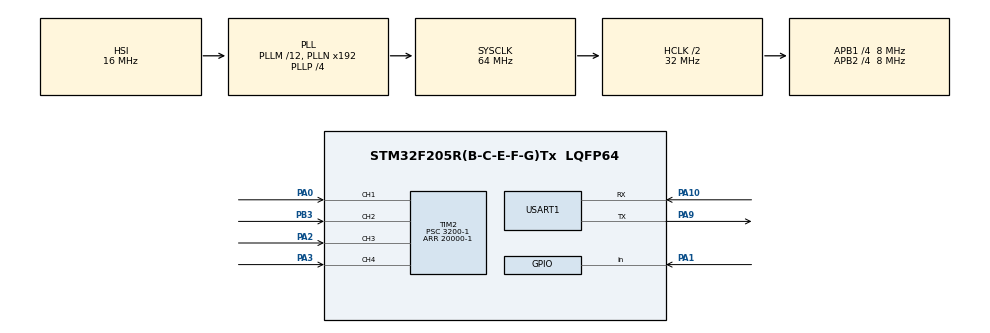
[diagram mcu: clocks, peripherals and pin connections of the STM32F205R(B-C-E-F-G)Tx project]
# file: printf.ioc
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Mcu.Family=STM32F2
Mcu.Name=STM32F205R(B-C-E-F-G)Tx
Mcu.Package=LQFP64
NVIC.PriorityGroup=NVIC_PRIORITYGROUP_4
NVIC.TIM2_IRQn=true\:0\:0\:false\:false\:true\:true\:true
PA0-WKUP.GPIO_ModeDefaultPP=GPIO_MODE_AF_OD
PA0-WKUP.GPIO_Speed=GPIO_SPEED_FREQ_VERY_HIGH
PA0-WKUP.Signal=S_TIM2_CH1_ETR
PA1.Signal=GPIO_Input
PA10.Mode=Asynchronous
PA10.Signal=USART1_RX
PA13.Mode=Serial_Wire
PA13.Signal=SYS_JTMS-SWDIO
PA14.Mode=Serial_Wire
PA14.Signal=SYS_JTCK-SWCLK
PA2.Signal=S_TIM2_CH3
PA3.Signal=S_TIM2_CH4
PA9.Mode=Asynchronous
PA9.Signal=USART1_TX
PB3.Signal=S_TIM2_CH2
PH0-OSC_IN.Mode=HSE-External-Oscillator
PH0-OSC_IN.Signal=RCC_OSC_IN
PH1-OSC_OUT.Mode=HSE-External-Oscillator
PH1-OSC_OUT.Signal=RCC_OSC_OUT
ProjectManager.HeapSize=0x200
ProjectManager.StackSize=0x400
ProjectManager.TargetToolchain=MDK-ARM V5
RCC.48MHZClocksFreq_Value=64000000
RCC.AHBCLKDivider=RCC_SYSCLK_DIV2
RCC.AHBFreq_Value=32000000
RCC.APB1CLKDivider=RCC_HCLK_DIV4
RCC.APB1Freq_Value=8000000
RCC.APB1TimFreq_Value=16000000
RCC.APB2CLKDivider=RCC_HCLK_DIV4
RCC.APB2Freq_Value=8000000
RCC.APB2TimFreq_Value=16000000
RCC.CortexFreq_Value=32000000
RCC.HCLKFreq_Value=32000000
RCC.HSE_VALUE=8000000
RCC.HSI_VALUE=16000000
RCC.LSE_VALUE=32768
RCC.PLLM=12
RCC.PLLP=RCC_PLLP_DIV4
RCC.SYSCLKFreq_VALUE=64000000
RCC.SYSCLKSource=RCC_SYSCLKSOURCE_PLLCLK
RCC.VCOOutputFreq_Value=256000000
SH.S_TIM2_CH1_ETR.0=TIM2_CH1,Input_Capture1_from_TI1
SH.S_TIM2_CH2.0=TIM2_CH2,Input_Capture2_from_TI2
SH.S_TIM2_CH3.0=TIM2_CH3,Input_Capture3_from_TI3
SH.S_TIM2_CH4.0=TIM2_CH4,Input_Capture4_from_TI4
TIM2.Channel-Input_Capture1_from_TI1=TIM_CHANNEL_1
TIM2.Channel-Input_Capture2_from_TI2=TIM_CHANNEL_2
TIM2.Channel-Input_Capture3_from_TI3=TIM_CHANNEL_3
TIM2.Channel-Input_Capture4_from_TI4=TIM_CHANNEL_4
TIM2.ICPolarity_CH1=TIM_INPUTCHANNELPOLARITY_BOTHEDGE
TIM2.ICPolarity_CH3=TIM_INPUTCHANNELPOLARITY_FALLING
TIM2.ICPolarity_CH4=TIM_INPUTCHANNELPOLARITY_BOTHEDGE
TIM2.Period=20000-1
TIM2.Prescaler=3200-1
USART1.VirtualMode=VM_ASYNC
board=custom

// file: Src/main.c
/* USER CODE BEGIN Header */
/**
  ******************************************************************************
  * @file           : main.c
  * @brief          : Main program body
  ******************************************************************************
  * @attention
  *
  * <h2><center>&copy; Copyright (c) 2019 STMicroelectronics.
  * All rights reserved.</center></h2>
  *
  * This software component is licensed by ST under BSD 3-Clause license,
  * the "License"; You may not use this file except in compliance with the
  * License. You may obtain a copy of the License at:
  *                        opensource.org/licenses/BSD-3-Clause
  *
  ******************************************************************************
  */
/* USER CODE END Header */

#include "main.h"

TIM_HandleTypeDef htim2;

UART_HandleTypeDef huart1;

/* USER CODE BEGIN PV */
uint16_t 	Channel1HighTime, Channel2HighTime, Channel3HighTime, Channel4HighTime;
uint16_t 	Channel1Period, Channel2Period, Channel3Period, Channel4Period;
uint8_t  	Channel1Edge = 0, Channel2Edge = 0, Channel3Edge = 0, Channel4Edge = 0;
uint16_t 	Channel1Percent, Channel2Percent, Channel3Percent, Channel4Percent;
uint16_t	Channel1PercentTemp[3] = {0, 0, 0};
uint8_t 	Channel1TempCount = 0;
uint16_t 	Channel1RisingTimeLast=0, Channel1RisingTimeNow, Channel1FallingTime;
uint16_t 	Channel2RisingTimeLast=0, Channel2RisingTimeNow, Channel2FallingTime;
uint16_t 	Channel3RisingTimeLast=0, Channel3RisingTimeNow, Channel3FallingTime;
uint16_t 	Channel4RisingTimeLast=0, Channel4RisingTimeNow, Channel4FallingTime;
/* USER CODE END PV */

void SystemClock_Config(void);
static void MX_GPIO_Init(void);
static void MX_USART1_UART_Init(void);
static void MX_TIM2_Init(void);

/* USER CODE BEGIN 0 */
int fputc(int ch,FILE *f)
{
uint8_t temp[1]={ch};
HAL_UART_Transmit(&huart1,temp,1,2);
return(ch);
}
/* USER CODE END 0 */

int main(void)
{

  /* MCU Configuration--------------------------------------------------------*/

  /* Reset of all peripherals, Initializes the Flash interface and the Systick. */
  HAL_Init();

  /* Configure the system clock */
  SystemClock_Config();

  /* Initialize all configured peripherals */
  MX_GPIO_Init();
  MX_USART1_UART_Init();
  MX_TIM2_Init();
	HAL_TIM_IC_Start_IT(&htim2, TIM_CHANNEL_1);
	HAL_TIM_IC_Start_IT(&htim2, TIM_CHANNEL_2);
	HAL_TIM_IC_Start_IT(&htim2, TIM_CHANNEL_3);
	HAL_TIM_IC_Start_IT(&htim2, TIM_CHANNEL_4);

  /* Infinite loop */
  while (1)
  {
//		printf("Channel1RisingTimeLast:%d\n",Channel1RisingTimeLast);
//		printf("Channel1RisingTimeNow:%d\n",Channel1RisingTimeNow);
//		printf("Channel1FallingTime:%d\n",Channel1FallingTime);
//		printf("\n\n");
//		printf("Channel2RisingTimeLast:%d\n",Channel2RisingTimeLast);
//		printf("Channel2RisingTimeNow:%d\n",Channel2RisingTimeNow);
//		printf("Channel2FallingTime:%d\n",Channel2FallingTime);
//		printf("\n\n");
//		printf("Channel3RisingTimeLast:%d\n",Channel3RisingTimeLast);
//		printf("Channel3RisingTimeNow:%d\n",Channel3RisingTimeNow);
//		printf("Channel3FallingTime:%d\n",Channel3FallingTime);
//		printf("\n\n");
//		printf("Channel4RisingTimeLast:%d\n",Channel4RisingTimeLast);
//		printf("Channel4RisingTimeNow:%d\n",Channel4RisingTimeNow);
//		printf("Channel4FallingTime:%d\n",Channel4FallingTime);
//		printf("\n\n");
//		HAL_Delay (3000);
  }
}

void SystemClock_Config(void)
{
  RCC_OscInitTypeDef RCC_OscInitStruct = {0};
  RCC_ClkInitTypeDef RCC_ClkInitStruct = {0};

  /** Initializes the CPU, AHB and APB busses clocks
  */
  RCC_OscInitStruct.OscillatorType = RCC_OSCILLATORTYPE_HSI;
  RCC_OscInitStruct.HSIState = RCC_HSI_ON;
  RCC_OscInitStruct.HSICalibrationValue = RCC_HSICALIBRATION_DEFAULT;
  RCC_OscInitStruct.PLL.PLLState = RCC_PLL_ON;
  RCC_OscInitStruct.PLL.PLLSource = RCC_PLLSOURCE_HSI;
  RCC_OscInitStruct.PLL.PLLM = 12;
  RCC_OscInitStruct.PLL.PLLN = 192;
  RCC_OscInitStruct.PLL.PLLP = RCC_PLLP_DIV4;
  RCC_OscInitStruct.PLL.PLLQ = 4;
  if (HAL_RCC_OscConfig(&RCC_OscInitStruct) != HAL_OK)
  {
    Error_Handler();
  }
  /** Initializes the CPU, AHB and APB busses clocks
  */
  RCC_ClkInitStruct.ClockType = RCC_CLOCKTYPE_HCLK|RCC_CLOCKTYPE_SYSCLK
                              |RCC_CLOCKTYPE_PCLK1|RCC_CLOCKTYPE_PCLK2;
  RCC_ClkInitStruct.SYSCLKSource = RCC_SYSCLKSOURCE_PLLCLK;
  RCC_ClkInitStruct.AHBCLKDivider = RCC_SYSCLK_DIV2;
  RCC_ClkInitStruct.APB1CLKDivider = RCC_HCLK_DIV4;
  RCC_ClkInitStruct.APB2CLKDivider = RCC_HCLK_DIV4;

  if (HAL_RCC_ClockConfig(&RCC_ClkInitStruct, FLASH_LATENCY_1) != HAL_OK)
  {
    Error_Handler();
  }
}

static void MX_TIM2_Init(void)
{

  TIM_MasterConfigTypeDef sMasterConfig = {0};
  TIM_IC_InitTypeDef sConfigIC = {0};

  htim2.Instance = TIM2;
  htim2.Init.Prescaler = 3200-1;
  htim2.Init.CounterMode = TIM_COUNTERMODE_UP;
  htim2.Init.Period = 20000-1;
  htim2.Init.ClockDivision = TIM_CLOCKDIVISION_DIV1;
  htim2.Init.AutoReloadPreload = TIM_AUTORELOAD_PRELOAD_DISABLE;
  if (HAL_TIM_IC_Init(&htim2) != HAL_OK)
  {
    Error_Handler();
  }
  sMasterConfig.MasterOutputTrigger = TIM_TRGO_RESET;
  sMasterConfig.MasterSlaveMode = TIM_MASTERSLAVEMODE_DISABLE;
  if (HAL_TIMEx_MasterConfigSynchronization(&htim2, &sMasterConfig) != HAL_OK)
  {
    Error_Handler();
  }
  sConfigIC.ICPolarity = TIM_INPUTCHANNELPOLARITY_BOTHEDGE;
  sConfigIC.ICSelection = TIM_ICSELECTION_DIRECTTI;
  sConfigIC.ICPrescaler = TIM_ICPSC_DIV1;
  sConfigIC.ICFilter = 0;
  if (HAL_TIM_IC_ConfigChannel(&htim2, &sConfigIC, TIM_CHANNEL_1) != HAL_OK)
  {
    Error_Handler();
  }
  sConfigIC.ICPolarity = TIM_INPUTCHANNELPOLARITY_RISING;
  if (HAL_TIM_IC_ConfigChannel(&htim2, &sConfigIC, TIM_CHANNEL_2) != HAL_OK)
  {
    Error_Handler();
  }
  sConfigIC.ICPolarity = TIM_INPUTCHANNELPOLARITY_FALLING;
  if (HAL_TIM_IC_ConfigChannel(&htim2, &sConfigIC, TIM_CHANNEL_3) != HAL_OK)
  {
    Error_Handler();
  }
  sConfigIC.ICPolarity = TIM_INPUTCHANNELPOLARITY_BOTHEDGE;
  if (HAL_TIM_IC_ConfigChannel(&htim2, &sConfigIC, TIM_CHANNEL_4) != HAL_OK)
  {
    Error_Handler();
  }

}

static void MX_USART1_UART_Init(void)
{

  huart1.Instance = USART1;
  huart1.Init.BaudRate = 115200;
  huart1.Init.WordLength = UART_WORDLENGTH_8B;
  huart1.Init.StopBits = UART_STOPBITS_1;
  huart1.Init.Parity = UART_PARITY_NONE;
  huart1.Init.Mode = UART_MODE_TX_RX;
  huart1.Init.HwFlowCtl = UART_HWCONTROL_NONE;
  huart1.Init.OverSampling = UART_OVERSAMPLING_16;
  if (HAL_UART_Init(&huart1) != HAL_OK)
  {
    Error_Handler();
  }

}

static void MX_GPIO_Init(void)
{
  GPIO_InitTypeDef GPIO_InitStruct = {0};

  /* GPIO Ports Clock Enable */
  __HAL_RCC_GPIOH_CLK_ENABLE();
  __HAL_RCC_GPIOA_CLK_ENABLE();
  __HAL_RCC_GPIOB_CLK_ENABLE();

  /*Configure GPIO pin : PA1 */
  GPIO_InitStruct.Pin = GPIO_PIN_1;
  GPIO_InitStruct.Mode = GPIO_MODE_INPUT;
  GPIO_InitStruct.Pull = GPIO_NOPULL;
  HAL_GPIO_Init(GPIOA, &GPIO_InitStruct);

}

void Error_Handler(void)
{
}

void HAL_TIM_IC_CaptureCallback(TIM_HandleTypeDef *htim)
{
  /* Prevent unused argument(s) compilation warning */
  UNUSED(htim);
  /* NOTE : This function Should not be modified, when the callback is needed,
            the __HAL_TIM_IC_CaptureCallback could be implemented in the user file
   */
	if(htim->Channel == HAL_TIM_ACTIVE_CHANNEL_1)
	{
		if(Channel1Edge == 0)
		{
			Channel1RisingTimeNow = HAL_TIM_ReadCapturedValue(&htim2, TIM_CHANNEL_1);//��ȡ������ʱ���
			__HAL_TIM_SET_CAPTUREPOLARITY(&htim2, TIM_CHANNEL_1, TIM_INPUTCHANNELPOLARITY_FALLING);//�л�������
			HAL_TIM_IC_Start_IT(&htim2, TIM_CHANNEL_1);
			Channel1Edge = 1;
			if(Channel1RisingTimeLast == 0)
			{
				Channel1Period = 0;
			}
			else
			{
				if(Channel1RisingTimeNow > Channel1RisingTimeLast)
				{
					Channel1Period = Channel1RisingTimeNow - Channel1RisingTimeLast;
				}
				else
				{
					Channel1Period = Channel1RisingTimeNow + 0xffff - Channel1RisingTimeLast + 1;
				}
			}
			Channel1RisingTimeLast = Channel1RisingTimeNow;
		}
		else if(Channel1Edge == 1)
		{
			Channel1FallingTime = HAL_TIM_ReadCapturedValue(&htim2, TIM_CHANNEL_1);
			__HAL_TIM_SET_CAPTUREPOLARITY(&htim2, TIM_CHANNEL_1, TIM_INPUTCHANNELPOLARITY_RISING);
			HAL_TIM_IC_Start_IT(&htim2, TIM_CHANNEL_1);

			if(Channel1FallingTime < Channel1RisingTimeNow)
			{
				Channel1HighTime = Channel1FallingTime + 0xffff - Channel1RisingTimeNow + 1;
			}
			else
			{
				Channel1HighTime = Channel1FallingTime - Channel1RisingTimeNow;
			}
			if(Channel1Period != 0)
			{
				Channel1Percent = (uint8_t)(((float)Channel1HighTime / Channel1Period) * 1000);
				printf("Channel1 = %d	", Channel1Percent);
			}
			Channel1Edge = 0;
		}
	}
	else if(htim->Channel == HAL_TIM_ACTIVE_CHANNEL_2)
	{
		if(Channel2Edge == 0)
		{
			Channel2RisingTimeNow = HAL_TIM_ReadCapturedValue(&htim2, TIM_CHANNEL_2);
			__HAL_TIM_SET_CAPTUREPOLARITY(&htim2, TIM_CHANNEL_2, TIM_INPUTCHANNELPOLARITY_FALLING);
			HAL_TIM_IC_Start_IT(&htim2, TIM_CHANNEL_2);
			Channel2Edge = 1;
			if(Channel2RisingTimeLast == 0)
			{
				Channel2Period = 0;
			}
			else
			{
				if(Channel2RisingTimeNow > Channel2RisingTimeLast)
				{
					Channel2Period = Channel2RisingTimeNow - Channel2RisingTimeLast;
				}
				else
				{
					Channel2Period = Channel2RisingTimeNow + 0xffff - Channel2RisingTimeLast + 1;
				}
			}
			Channel2RisingTimeLast = Channel2RisingTimeNow;
		}
		else if(Channel2Edge == 1)
		{
			Channel2FallingTime = HAL_TIM_ReadCapturedValue(&htim2, TIM_CHANNEL_2);
			__HAL_TIM_SET_CAPTUREPOLARITY(&htim2, TIM_CHANNEL_2, TIM_INPUTCHANNELPOLARITY_RISING);
			HAL_TIM_IC_Start_IT(&htim2, TIM_CHANNEL_2);

			if(Channel2FallingTime < Channel2RisingTimeNow)
			{
				Channel2HighTime = Channel2FallingTime + 0xffff - Channel2RisingTimeNow + 1;
			}
			else
			{
				Channel2HighTime = Channel2FallingTime - Channel2RisingTimeNow;
			}
			if(Channel2Period != 0)
			{
				Channel2Percent = (uint8_t)(((float)Channel2HighTime / Channel2Period) * 1000);
				printf("Channel2 = %d	", Channel2Percent);
			}
			Channel2Edge = 0;
		}
	}
	else if(htim->Channel == HAL_TIM_ACTIVE_CHANNEL_3)
	{
		if(Channel3Edge == 0)
		{
			Channel3RisingTimeNow = HAL_TIM_ReadCapturedValue(&htim2, TIM_CHANNEL_3);
			__HAL_TIM_SET_CAPTUREPOLARITY(&htim2, TIM_CHANNEL_3, TIM_INPUTCHANNELPOLARITY_FALLING);
			HAL_TIM_IC_Start_IT(&htim2, TIM_CHANNEL_3);
			Channel3Edge = 1;
			if(Channel3RisingTimeLast == 0)
			{
				Channel3Period = 0;
			}
			else
			{
				if(Channel3RisingTimeNow > Channel3RisingTimeLast)
				{
					Channel3Period = Channel3RisingTimeNow - Channel3RisingTimeLast;
				}
				else
				{
					Channel3Period = Channel3RisingTimeNow + 0xffff - Channel3RisingTimeLast + 1;
				}
			}
			Channel3RisingTimeLast = Channel3RisingTimeNow;
		}
		else if(Channel3Edge == 1)
		{
			Channel3FallingTime = HAL_TIM_ReadCapturedValue(&htim2, TIM_CHANNEL_3);
			__HAL_TIM_SET_CAPTUREPOLARITY(&htim2, TIM_CHANNEL_3, TIM_INPUTCHANNELPOLARITY_RISING);
			HAL_TIM_IC_Start_IT(&htim2, TIM_CHANNEL_3);

			if(Channel3FallingTime < Channel3RisingTimeNow)
			{
				Channel3HighTime = Channel3FallingTime + 0xffff - Channel3RisingTimeNow + 1;
			}
			else
			{
				Channel3HighTime = Channel3FallingTime - Channel3RisingTimeNow;
			}
			if(Channel3Period != 0)
			{
				Channel3Percent = (uint8_t)(((float)Channel3HighTime / Channel3Period) * 1000);
				printf("Channel3 = %d	", Channel3Percent);
			}
			Channel3Edge = 0;
		}
	}
	else if(htim->Channel == HAL_TIM_ACTIVE_CHANNEL_4)
	{
		if(Channel4Edge == 0)
		{
			Channel4RisingTimeNow = HAL_TIM_ReadCapturedValue(&htim2, TIM_CHANNEL_4);
			__HAL_TIM_SET_CAPTUREPOLARITY(&htim2, TIM_CHANNEL_4, TIM_INPUTCHANNELPOLARITY_FALLING);
			HAL_TIM_IC_Start_IT(&htim2, TIM_CHANNEL_4);
			Channel4Edge = 1;
			if(Channel4RisingTimeLast == 0)
			{
				Channel4Period = 0;
			}
			else
			{
				if(Channel4RisingTimeNow > Channel4RisingTimeLast)
				{
					Channel4Period = Channel4RisingTimeNow - Channel4RisingTimeLast;
				}
				else
				{
					Channel4Period = Channel4RisingTimeNow + 0xffff - Channel4RisingTimeLast + 1;
				}
			}
			Channel4RisingTimeLast = Channel4RisingTimeNow;
		}
		else if(Channel4Edge == 1)
		{
			Channel4FallingTime = HAL_TIM_ReadCapturedValue(&htim2, TIM_CHANNEL_4);
			__HAL_TIM_SET_CAPTUREPOLARITY(&htim2, TIM_CHANNEL_4, TIM_INPUTCHANNELPOLARITY_RISING);
			HAL_TIM_IC_Start_IT(&htim2, TIM_CHANNEL_4);

			if(Channel4FallingTime < Channel4RisingTimeNow)
			{
				Channel4HighTime = Channel4FallingTime + 0xffff - Channel4RisingTimeNow + 1;
			}
			else
			{
				Channel4HighTime = Channel4FallingTime - Channel4RisingTimeNow;
			}
			if(Channel4Period != 0)
			{
				Channel4Percent = (uint8_t)(((float)Channel4HighTime / Channel4Period) * 1000);
				printf("Channel4 = %d\n", Channel4Percent);
			}
			Channel4Edge = 0;
		}
	}
}

/************************ (C) COPYRIGHT STMicroelectronics *****END OF FILE****/
